# F28x7x_trig_regs register map
Vendor: Texas Instruments
Peripheral module from a debugger description file (folder C2000).
Address unit: 16 bits
Registers are 16-bit, read-write, no defined reset value unless marked. A register's access mark holds for its fields unless they carry their own. Offsets are as the file gives them; lines under a group give offsets from that group; [hi:lo] are bit positions; {n}, {i} and the like mark numbered series; 'fields as' and 'values as' point back to an identical list; <NAME> marks a mode.

## TRIG_REGS
0x00 INPUT1SELECT — INPUT1 Input Select Register (GPIO0 to x)
  [15:0] SELECT — Select GPIO for INPUT1 signal
0x01 INPUT2SELECT — INPUT2 Input Select Register (GPIO0 to x)
  [15:0] SELECT — Select GPIO for INPUT2 signal
0x02 INPUT3SELECT — INPUT3 Input Select Register (GPIO0 to x)
  [15:0] SELECT — Select GPIO for INPUT3 signal
0x03 INPUT4SELECT — INPUT4 Input Select Register (GPIO0 to x)
  [15:0] SELECT — Select GPIO for INPUT4 signal
0x04 INPUT5SELECT — INPUT5 Input Select Register (GPIO0 to x)
  [15:0] SELECT — Select GPIO for INPUT5 signal
0x05 INPUT6SELECT — INPUT6 Input Select Register (GPIO0 to x)
  [15:0] SELECT — Select GPIO for INPUT6 signal
0x06 INPUT7SELECT — INPUT7 Input Select Register (GPIO0 to x)
  [15:0] SELECT — Select GPIO for INPUT7 signal
0x07 INPUT8SELECT — INPUT8 Input Select Register (GPIO0 to x)
  [15:0] SELECT — Select GPIO for INPUT8 signal
0x08 INPUT9SELECT — INPUT9 Input Select Register (GPIO0 to x)
  [15:0] SELECT — Select GPIO for INPUT9 signal
0x09 INPUT10SELECT — INPUT10 Input Select Register (GPIO0 to x)
  [15:0] SELECT — Select GPIO for INPUT10 signal
0x0A INPUT11SELECT — INPUT11 Input Select Register (GPIO0 to x)
  [15:0] SELECT — Select GPIO for INPUT11 signal
0x0B INPUT12SELECT — INPUT12 Input Select Register (GPIO0 to x)
  [15:0] SELECT — Select GPIO for INPUT12 signal
0x0C INPUT13SELECT — INPUT13 Input Select Register (GPIO0 to x)
  [15:0] SELECT — Select GPIO for INPUT13 signal
0x0D INPUT14SELECT — INPUT14 Input Select Register (GPIO0 to x)
  [15:0] SELECT — Select GPIO for INPUT14 signal
0x0E INPUT15SELECT — INPUT15 Input Select Register (GPIO0 to x)
  [15:0] SELECT — Select GPIO for INPUT15 signal
0x0F INPUT16SELECT — INPUT16 Input Select Register (GPIO0 to x)
  [15:0] SELECT — Select GPIO for INPUT16 signal
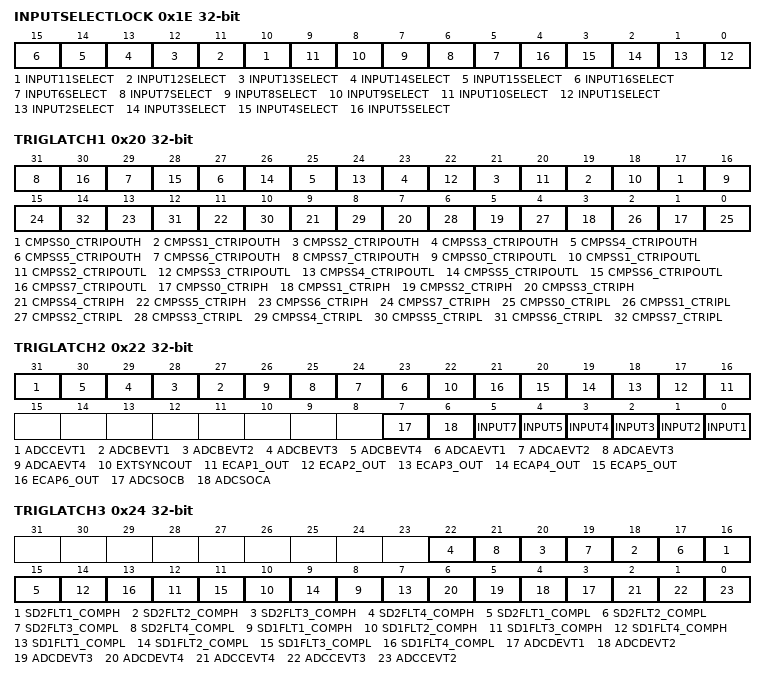
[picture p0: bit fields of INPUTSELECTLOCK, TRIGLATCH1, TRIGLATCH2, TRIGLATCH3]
0x1E INPUTSELECTLOCK 32-bit
  [n-1] INPUT{n}SELECT (n=11..16) — Lock bit for INPUT{n}SEL Register
  [n-1] INPUT{n}SELECT (n=6..10) — Lock bit for INPUT{n+1}SEL Register
  [n-1] INPUT{n}SELECT (n=1..5) — Lock bit for INPUT{n}SEL Register
0x20 TRIGLATCH1 32-bit — X-Bar Input Latch Register 1
  [2n+17] CMPSS{n}_CTRIPOUTH (n=0..7) — Input Latch for CMPSS{n}.CTRIPOUTH Signal
  [2n+16] CMPSS{n}_CTRIPOUTL (n=0..7) — Input Latch for CMPSS{n}.CTRIPOUTL Signal
  [2n+1] CMPSS{n}_CTRIPH (n=0..7) — Input Latch for CMPSS{n}.CTRIPH Signal
  [2n] CMPSS{n}_CTRIPL (n=0..7) — Input Latch for CMPSS{n}.CTRIPL Signal
0x22 TRIGLATCH2 32-bit — X-Bar Input Latch Register 2
  [31] ADCCEVT1 — Input Latch for ADCCEVT1 Signal
  [n+26] ADCBEVT{n} (n=1..4) — Input Latch for ADCBEVT{n} Signal
  [n+22] ADCAEVT{n} (n=1..4) — Input Latch for ADCAEVT{n} Signal
  [22] EXTSYNCOUT — Input Latch for EXTSYNCOUT Signal
  [n+15] ECAP{n}_OUT (n=1..6) — Input Latch for ECAP{n}.OUT Signal
  [7] ADCSOCB — Input Latch for ADCSOCB Signal
  [6] ADCSOCA — Input Latch for ADCSOCA Signal
  [5] INPUT7 — Input Latch for INPUT7 Signal
  [n-1] INPUT{n} (n=1..5) — Input Latch for INPUT{n} Signal
0x24 TRIGLATCH3 32-bit — X-Bar Input Latch Register 3
  [2n+14] SD2FLT{n}_COMPH (n=1..4) — Input Latch for SD2FLT{n}.COMPH Signal
  [2n+13] SD2FLT{n}_COMPL (n=1..4) — Input Latch for SD2FLT{n}.COMPL Signal
  [2n+6] SD1FLT{n}_COMPH (n=1..4) — Input Latch for SD1FLT{n}.COMPH Signal
  [2n+5] SD1FLT{n}_COMPL (n=1..4) — Input Latch for SD1FLT{n}.COMPL Signal
  [n+2] ADCDEVT{n} (n=1..4) — Input Latch for ADCDEVT{n} Signal
  [2] ADCCEVT4 — Input Latch for ADCCEVT4 Signal
  [1] ADCCEVT3 — Input Latch for ADCCEVT3 Signal
  [0] ADCCEVT2 — Input Latch for ADCCEVT2 Signal
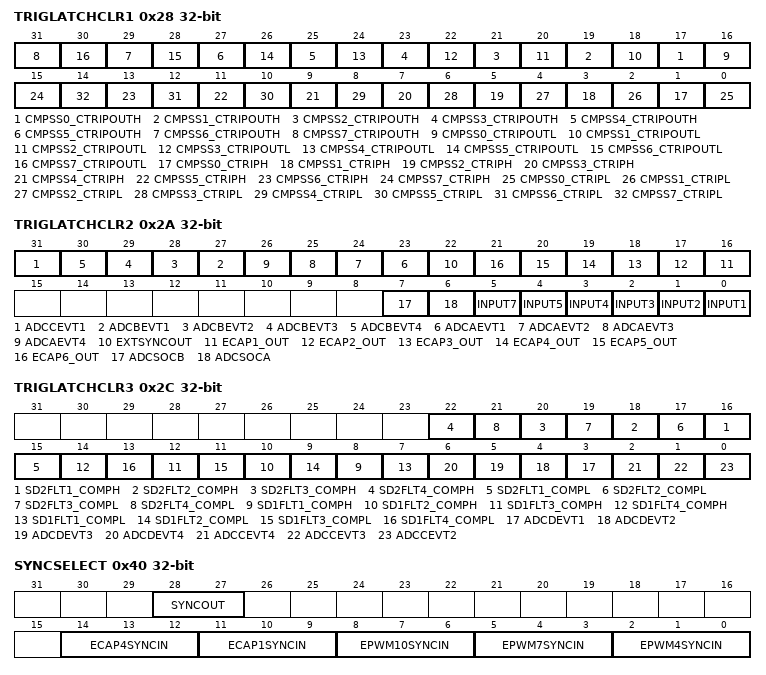
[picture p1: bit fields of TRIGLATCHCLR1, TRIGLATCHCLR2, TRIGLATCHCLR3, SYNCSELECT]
0x28 TRIGLATCHCLR1 32-bit — X-Bar Input Latch Clear Register 1
  [2n+17] CMPSS{n}_CTRIPOUTH (n=0..7) — Input Latch Clear for CMPSS{n}.CTRIPOUTH Signal
  [2n+16] CMPSS{n}_CTRIPOUTL (n=0..7) — Input Latch Clear for CMPSS{n}.CTRIPOUTL Signal
  [2n+1] CMPSS{n}_CTRIPH (n=0..7) — Input Latch Clear for CMPSS{n}.CTRIPH Signal
  [2n] CMPSS{n}_CTRIPL (n=0..7) — Input Latch Clear for CMPSS{n}.CTRIPL Signal
0x2A TRIGLATCHCLR2 32-bit — X-Bar Input Latch Clear Register 2
  [31] ADCCEVT1 — Input Latch Clear for ADCCEVT1 Signal
  [n+26] ADCBEVT{n} (n=1..4) — Input Latch Clear for ADCBEVT{n} Signal
  [n+22] ADCAEVT{n} (n=1..4) — Input Latch Clear for ADCAEVT{n} Signal
  [22] EXTSYNCOUT — Input Latch Clear for EXTSYNCOUT Signal
  [n+15] ECAP{n}_OUT (n=1..6) — Input Latch Clear for ECAP{n}.OUT Signal
  [7] ADCSOCB — Input Latch Clear for ADCSOCB Signal
  [6] ADCSOCA — Input Latch Clear for ADCSOCA Signal
  [5] INPUT7 — Input Latch Clear for INPUT7 Signal
  [n-1] INPUT{n} (n=1..5) — Input Latch Clear for INPUT{n} Signal
0x2C TRIGLATCHCLR3 32-bit — X-Bar Input Latch Clear Register 3
  [2n+14] SD2FLT{n}_COMPH (n=1..4) — Input Latch Clear for SD2FLT{n}.COMPH Signal
  [2n+13] SD2FLT{n}_COMPL (n=1..4) — Input Latch Clear for SD2FLT{n}.COMPL Signal
  [2n+6] SD1FLT{n}_COMPH (n=1..4) — Input Latch Clear for SD1FLT{n}.COMPH Signal
  [2n+5] SD1FLT{n}_COMPL (n=1..4) — Input Latch Clear for SD1FLT{n}.COMPL Signal
  [n+2] ADCDEVT{n} (n=1..4) — Input Latch Clear for ADCDEVT{n} Signal
  [2] ADCCEVT4 — Input Latch Clear for ADCCEVT4 Signal
  [1] ADCCEVT3 — Input Latch Clear for ADCCEVT3 Signal
  [0] ADCCEVT2 — Input Latch Clear for ADCCEVT2 Signal
0x40 SYNCSELECT 32-bit — Sync Input and Output Select Register
  [28:27] SYNCOUT — Select Syncout Source
  [14:12] ECAP4SYNCIN — Selects Sync Input Source for ECAP4
  [11:9] ECAP1SYNCIN — Selects Sync Input Source for ECAP1
  [8:6] EPWM10SYNCIN — Selects Sync Input Source for EPWM10
  [5:3] EPWM7SYNCIN — Selects Sync Input Source for EPWM7
  [2:0] EPWM4SYNCIN — Selects Sync Input Source for EPWM4
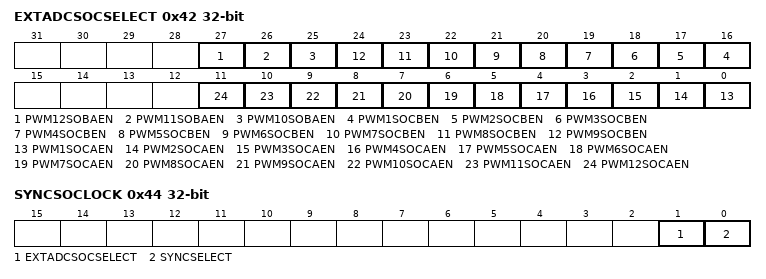
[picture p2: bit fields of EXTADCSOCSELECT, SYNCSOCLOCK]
0x42 EXTADCSOCSELECT 32-bit — External ADCSOC Select Register
  [27] PWM12SOBAEN — PWM12SOBAEN Enable for ADCSOCBOn
  [26] PWM11SOBAEN — PWM11SOBAEN Enable for ADCSOCBOn
  [25] PWM10SOBAEN — PWM10SOBAEN Enable for ADCSOCBOn
  [n+15] PWM{n}SOCBEN (n=1..9) — PWM{n}SOCBEN Enable for ADCSOCBOn
  [n-1] PWM{n}SOCAEN (n=1..12) — PWM{n}SOCAEN Enable for ADCSOCAOn
0x44 SYNCSOCLOCK 32-bit — SYNCSEL and EXTADCSOC Select Lock register
  [1] EXTADCSOCSELECT — EXTADCSOCSEL Register Lock bit
  [0] SYNCSELECT — SYNCSEL Register Lock bit
